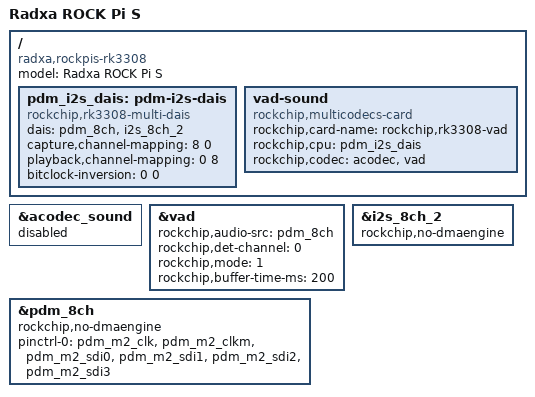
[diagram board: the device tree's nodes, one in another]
/dts-v1/;
/plugin/;

/ {
	model = "Radxa ROCK Pi S";
	compatible = "radxa,rockpis-rk3308", "rockchip,rk3308";

	fragment@0 {
		target-path = "/";
		__overlay__ {
			pdm_i2s_dais: pdm-i2s-dais {
				status = "okay";
				#sound-dai-cells = <0>;
				compatible = "rockchip,rk3308-multi-dais", "rockchip,multi-dais";
				dais = <&pdm_8ch>, <&i2s_8ch_2>;
				capture,channel-mapping = <8 0>;
				playback,channel-mapping = <0 8>;
				bitclock-inversion = <0 0>;
			};

			vad-sound {
				status = "okay";
				compatible = "rockchip,multicodecs-card";
				rockchip,card-name = "rockchip,rk3308-vad";
				rockchip,cpu = <&pdm_i2s_dais>;
				rockchip,codec = <&acodec>, <&vad>;
			};
		};
	};

	fragment@1 {
		target = <&acodec_sound>;
		__overlay__ {
			status = "disabled";
		};
	};

	fragment@2 {
		target = <&vad>;
		__overlay__ {
			status = "okay";
			rockchip,audio-src = <&pdm_8ch>;
			rockchip,det-channel = <0>;
			rockchip,mode = <1>;
			rockchip,buffer-time-ms = <200>;
			#sound-dai-cells = <0>;
		};
	};

	fragment@3 {
		target = <&pdm_8ch>;
		__overlay__ {
			status = "okay";
			#sound-dai-cells = <0>;
			rockchip,no-dmaengine;
			pinctrl-names = "default";
			pinctrl-0 = <&pdm_m2_clk
					 &pdm_m2_clkm
					 &pdm_m2_sdi0
					 &pdm_m2_sdi1
					 &pdm_m2_sdi2
					 &pdm_m2_sdi3>;
		};
	};

	fragment@4 {
		target = <&i2s_8ch_2>;
		__overlay__ {
			rockchip,no-dmaengine;
		};
	};

};
